VERSION ""

NS_ :

BS_:

BU_: TEST ESP

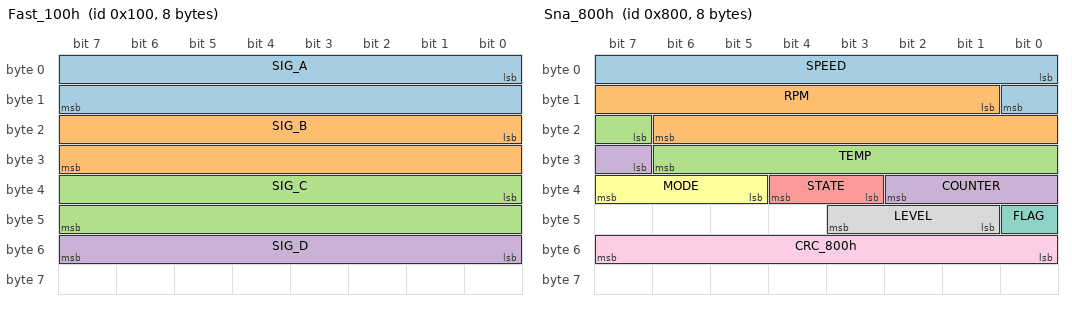
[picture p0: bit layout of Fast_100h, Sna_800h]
BO_ 256 Fast_100h: 8 TEST
 SG_ SIG_A : 0|16@1+ (0.1,0) [0|6553.5] "rpm"  ESP
 SG_ SIG_B : 16|16@1+ (0.1,0) [0|6553.5] "°C"  ESP
 SG_ SIG_C : 32|16@1- (1,0) [-100|100] ""  ESP
 SG_ SIG_D : 48|8@1+ (1,0) [0|255] "bar"  ESP

BO_ 512 Irr_200h: 8 TEST
 SG_ JITTER : 0|16@1+ (1,0) [0|0] "Nm"  ESP

BO_ 768 Sparse_300h: 8 TEST
 SG_ MODE M : 0|8@1+ (1,0) [0|0] ""  ESP
 SG_ SLOW m0 : 8|16@1+ (1,0) [0|0] "min"  ESP

CM_ BO_ 256 "Message comment, not a signal description";
CM_ SG_ 256 SIG_A "Motordrehzahl hinten";
CM_ SG_ 256 SIG_B "Öltemperatur Getriebe";
CM_ SG_ 512 JITTER "Torque with
a comment over two lines";
CM_ SG_ 768 SLOW "Minute counter; contains \"quotes\"";
VAL_ 768 MODE 0 "off" 1 "on" ;

BO_ 2048 Sna_800h: 8 TEST
 SG_ SPEED : 0|9@1+ (1,0) [0|511] "km/h"  ESP
 SG_ RPM : 9|14@1+ (0.5,0) [0|8191.5] "1/min"  ESP
 SG_ TEMP : 23|8@1- (1,0) [-128|127] "degC"  ESP
 SG_ COUNTER : 31|4@1+ (1,0) [0|15] ""  ESP
 SG_ STATE : 35|2@1+ (1,0) [0|3] ""  ESP
 SG_ MODE : 37|3@1+ (1,0) [0|7] ""  ESP
 SG_ FLAG : 40|1@1+ (1,0) [0|1] ""  ESP
 SG_ LEVEL : 41|3@1+ (1,0) [0|7] ""  ESP
 SG_ CRC_800h : 48|8@1+ (1,0) [0|255] ""  ESP

BA_DEF_ SG_  "GenSigSNA" STRING ;
BA_DEF_DEF_  "GenSigSNA" "";
BA_ "GenSigSNA" SG_ 2048 SPEED "1FFh";
BA_ "GenSigSNA" SG_ 2048 RPM "3FFFh";
BA_ "GenSigSNA" SG_ 2048 TEMP "80h";
BA_ "GenSigSNA" SG_ 2048 COUNTER "0h";
BA_ "GenSigSNA" SG_ 2048 STATE "0h";
BA_ "GenSigSNA" SG_ 2048 MODE "7h";
BA_ "GenSigSNA" SG_ 2048 FLAG "1h";
BA_ "GenSigSNA" SG_ 2048 LEVEL "1h";
BA_ "GenSigSNA" SG_ 2048 CRC_800h "FFh";
VAL_ 2048 SPEED 511 "SNV" ;
VAL_ 2048 STATE 0 "SNA" 1 "ON" 2 "OFF" ;
VAL_ 2048 MODE 6 "SNV" 1 "ON" ;
VAL_ 2048 LEVEL 1 "OK" 7 "SNV" ;

BO_ 2592 Ign_A20h: 8 VCU
 SG_ MODE : 0|4@1+ (1,0) [0|15] ""  VCU
VAL_ 2592 MODE 0 "NONE" 1 "CHARGE" 3 "KEYON: Ignition on" 15 "SNA" ;

BO_ 2593 Tmp_A21h: 8 VCU
 SG_ TEMP : 0|8@1+ (1,0) [0|255] "degC"  VCU
VAL_ 2593 TEMP 254 "SENSOR_DEF" 255 "SNA" ;

BO_ 2832 Cyc_B10h: 8 VCU
 SG_ CYC : 0|8@1+ (1,0) [0|255] "" VCU

BO_ 2833 Evt_B11h: 8 VCU
 SG_ EVT : 0|8@1+ (1,0) [0|255] "" VCU

BA_DEF_ BO_  "GenMsgCycleTime" INT 0 65535;
BA_DEF_DEF_  "GenMsgCycleTime" 0;
BA_ "GenMsgCycleTime" BO_ 2832 20;
